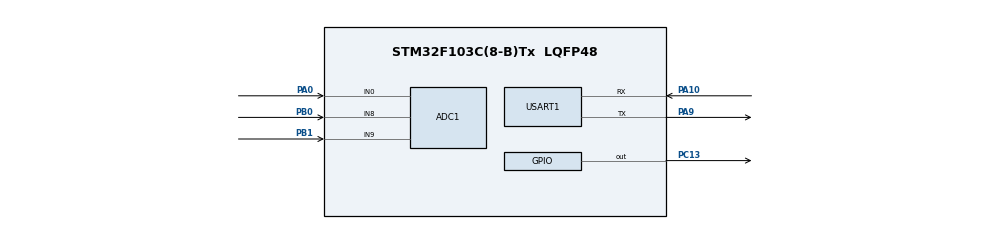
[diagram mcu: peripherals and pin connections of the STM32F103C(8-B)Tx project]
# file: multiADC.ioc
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ADC1.Channel-0\#ChannelRegularConversion=ADC_CHANNEL_0
ADC1.Channel-1\#ChannelRegularConversion=ADC_CHANNEL_0
ADC1.Channel-2\#ChannelRegularConversion=ADC_CHANNEL_0
ADC1.Channel-3\#ChannelRegularConversion=ADC_CHANNEL_0
ADC1.NbrOfConversion=4
ADC1.NbrOfConversionFlag=1
ADC1.Rank-0\#ChannelRegularConversion=1
ADC1.Rank-1\#ChannelRegularConversion=2
ADC1.Rank-2\#ChannelRegularConversion=3
ADC1.Rank-3\#ChannelRegularConversion=4
ADC1.SamplingTime-0\#ChannelRegularConversion=ADC_SAMPLETIME_1CYCLE_5
ADC1.SamplingTime-1\#ChannelRegularConversion=ADC_SAMPLETIME_1CYCLE_5
ADC1.SamplingTime-2\#ChannelRegularConversion=ADC_SAMPLETIME_1CYCLE_5
ADC1.SamplingTime-3\#ChannelRegularConversion=ADC_SAMPLETIME_1CYCLE_5
ADC1.master=1
Mcu.Family=STM32F1
Mcu.Name=STM32F103C(8-B)Tx
Mcu.Package=LQFP48
NVIC.ADC1_2_IRQn=true\:0\:0\:false\:false\:true\:true\:true
NVIC.PriorityGroup=NVIC_PRIORITYGROUP_4
PA0-WKUP.Signal=ADCx_IN0
PA10.Mode=Asynchronous
PA10.Signal=USART1_RX
PA9.Mode=Asynchronous
PA9.Signal=USART1_TX
PB0.Signal=ADCx_IN8
PB1.Signal=ADCx_IN9
PC13-TAMPER-RTC.Signal=GPIO_Output
ProjectManager.HeapSize=0x200
ProjectManager.StackSize=0x400
ProjectManager.TargetToolchain=Makefile
RCC.APB1Freq_Value=8000000
RCC.APB2Freq_Value=8000000
SH.ADCx_IN0.0=ADC1_IN0,IN0
SH.ADCx_IN8.0=ADC1_IN8,IN8
SH.ADCx_IN9.0=ADC1_IN9,IN9
USART1.VirtualMode=VM_ASYNC
VP_SYS_VS_ND.Mode=No_Debug
board=custom

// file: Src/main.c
/* USER CODE BEGIN Header */
/**
  ******************************************************************************
  * @file           : main.c
  * @brief          : Main program body
  ******************************************************************************
  ** This notice applies to any and all portions of this file
  * that are not between comment pairs USER CODE BEGIN and
  * USER CODE END. Other portions of this file, whether
  * inserted by the user or by software development tools
  * are owned by their respective copyright owners.
  *
  * COPYRIGHT(c) 2019 STMicroelectronics
  *
  * Redistribution and use in source and binary forms, with or without modification,
  * are permitted provided that the following conditions are met:
  *   1. Redistributions of source code must retain the above copyright notice,
  *      this list of conditions and the following disclaimer.
  *   2. Redistributions in binary form must reproduce the above copyright notice,
  *      this list of conditions and the following disclaimer in the documentation
  *      and/or other materials provided with the distribution.
  *   3. Neither the name of STMicroelectronics nor the names of its contributors
  *      may be used to endorse or promote products derived from this software
  *      without specific prior written permission.
  *
  * THIS SOFTWARE IS PROVIDED BY THE COPYRIGHT HOLDERS AND CONTRIBUTORS "AS IS"
  * AND ANY EXPRESS OR IMPLIED WARRANTIES, INCLUDING, BUT NOT LIMITED TO, THE
  * IMPLIED WARRANTIES OF MERCHANTABILITY AND FITNESS FOR A PARTICULAR PURPOSE ARE
  * DISCLAIMED. IN NO EVENT SHALL THE COPYRIGHT HOLDER OR CONTRIBUTORS BE LIABLE
  * FOR ANY DIRECT, INDIRECT, INCIDENTAL, SPECIAL, EXEMPLARY, OR CONSEQUENTIAL
  * DAMAGES (INCLUDING, BUT NOT LIMITED TO, PROCUREMENT OF SUBSTITUTE GOODS OR
  * SERVICES; LOSS OF USE, DATA, OR PROFITS; OR BUSINESS INTERRUPTION) HOWEVER
  * CAUSED AND ON ANY THEORY OF LIABILITY, WHETHER IN CONTRACT, STRICT LIABILITY,
  * OR TORT (INCLUDING NEGLIGENCE OR OTHERWISE) ARISING IN ANY WAY OUT OF THE USE
  * OF THIS SOFTWARE, EVEN IF ADVISED OF THE POSSIBILITY OF SUCH DAMAGE.
  *
  ******************************************************************************
  */
/* USER CODE END Header */

#include "main.h"

ADC_HandleTypeDef hadc1;

UART_HandleTypeDef huart1;

/* USER CODE BEGIN PV */
int count = 0;
uint16_t val[2];
uint8_t serial[4];
/* USER CODE END PV */

void SystemClock_Config(void);
static void MX_GPIO_Init(void);
static void MX_ADC1_Init(void);
static void MX_USART1_UART_Init(void);

int main(void)
{

  /* MCU Configuration--------------------------------------------------------*/

  /* Reset of all peripherals, Initializes the Flash interface and the Systick. */
  HAL_Init();

  /* Configure the system clock */
  SystemClock_Config();

  /* Initialize all configured peripherals */
  MX_GPIO_Init();
  MX_ADC1_Init();
  MX_USART1_UART_Init();

  /* Infinite loop */
  while (1)
  {
	HAL_ADC_Start(&hadc1);
	HAL_ADC_PollForConversion(&hadc1, 1000);
	val[0] = HAL_ADC_GetValue(&hadc1);

	HAL_ADC_PollForConversion(&hadc1, 1000);
	val[1] = HAL_ADC_GetValue(&hadc1);

	HAL_ADC_Stop(&hadc1);

	HAL_GPIO_TogglePin(GPIOC, GPIO_PIN_13);

	serial[0] = (uint8_t) ((val[0] >> 8) & 0xFF);
	serial[1] = (uint8_t) ((val[0] >> 0) & 0xFF);
	serial[2] = (uint8_t) ((val[1] >> 8) & 0xFF);
	serial[3] = (uint8_t) ((val[1] >> 0) & 0xFF);

	HAL_UART_Transmit(&huart1, serial, sizeof(serial), 1000);

	HAL_Delay(250);
  }
}

void HAL_ADC_ConvCpltCallback(ADC_HandleTypeDef* hadc) {

	/*if ((count % 2) == 0) {
		sConfig.Channel = ADC_CHANNEL_0;
		sConfig.Rank = ADC_REGULAR_RANK_1;
		sConfig.SamplingTime = ADC_SAMPLETIME_1CYCLE_5;
		HAL_ADC_ConfigChannel(&hadc1, &sConfig);
	}

	if (count % 2) {
		sConfig.Channel = ADC_CHANNEL_1;
		sConfig.Rank = ADC_REGULAR_RANK_1;
		sConfig.SamplingTime = ADC_SAMPLETIME_1CYCLE_5;
		HAL_ADC_ConfigChannel(&hadc1, &sConfig);
	}*/

	//count++;

	/*int val = HAL_ADC_GetValue(&hadc1);
	if (val > 2000) {
		HAL_GPIO_TogglePin(GPIOC, GPIO_PIN_13);
	}*/

}

void SystemClock_Config(void)
{
  RCC_OscInitTypeDef RCC_OscInitStruct = {0};
  RCC_ClkInitTypeDef RCC_ClkInitStruct = {0};
  RCC_PeriphCLKInitTypeDef PeriphClkInit = {0};

  /** Initializes the CPU, AHB and APB busses clocks
  */
  RCC_OscInitStruct.OscillatorType = RCC_OSCILLATORTYPE_HSI;
  RCC_OscInitStruct.HSIState = RCC_HSI_ON;
  RCC_OscInitStruct.HSICalibrationValue = RCC_HSICALIBRATION_DEFAULT;
  RCC_OscInitStruct.PLL.PLLState = RCC_PLL_NONE;
  if (HAL_RCC_OscConfig(&RCC_OscInitStruct) != HAL_OK)
  {
    Error_Handler();
  }
  /** Initializes the CPU, AHB and APB busses clocks
  */
  RCC_ClkInitStruct.ClockType = RCC_CLOCKTYPE_HCLK|RCC_CLOCKTYPE_SYSCLK
                              |RCC_CLOCKTYPE_PCLK1|RCC_CLOCKTYPE_PCLK2;
  RCC_ClkInitStruct.SYSCLKSource = RCC_SYSCLKSOURCE_HSI;
  RCC_ClkInitStruct.AHBCLKDivider = RCC_SYSCLK_DIV1;
  RCC_ClkInitStruct.APB1CLKDivider = RCC_HCLK_DIV1;
  RCC_ClkInitStruct.APB2CLKDivider = RCC_HCLK_DIV1;

  if (HAL_RCC_ClockConfig(&RCC_ClkInitStruct, FLASH_LATENCY_0) != HAL_OK)
  {
    Error_Handler();
  }
  PeriphClkInit.PeriphClockSelection = RCC_PERIPHCLK_ADC;
  PeriphClkInit.AdcClockSelection = RCC_ADCPCLK2_DIV2;
  if (HAL_RCCEx_PeriphCLKConfig(&PeriphClkInit) != HAL_OK)
  {
    Error_Handler();
  }
}

static void MX_ADC1_Init(void)
{

  ADC_ChannelConfTypeDef sConfig = {0};

  /** Common config
  */
  hadc1.Instance = ADC1;
  hadc1.Init.ScanConvMode = ENABLE; // enable to read from different ranks
  hadc1.Init.ContinuousConvMode = ENABLE;
  hadc1.Init.DiscontinuousConvMode = DISABLE;
  hadc1.Init.ExternalTrigConv = ADC_SOFTWARE_START;
  hadc1.Init.DataAlign = ADC_DATAALIGN_RIGHT;
  hadc1.Init.NbrOfConversion = 2;
  if (HAL_ADC_Init(&hadc1) != HAL_OK)
  {
    Error_Handler();
  }
  /** Configure Regular Channel
  */
  sConfig.Channel = ADC_CHANNEL_0;
  sConfig.Rank = ADC_REGULAR_RANK_1;
  sConfig.SamplingTime = ADC_SAMPLETIME_1CYCLE_5;
  if (HAL_ADC_ConfigChannel(&hadc1, &sConfig) != HAL_OK)
  {
    Error_Handler();
  }
  /** Configure Regular Channel
  */
  sConfig.Channel = ADC_CHANNEL_1;
  sConfig.Rank = ADC_REGULAR_RANK_2;
  if (HAL_ADC_ConfigChannel(&hadc1, &sConfig) != HAL_OK)
  {
    Error_Handler();
  }

}

static void MX_USART1_UART_Init(void)
{

  huart1.Instance = USART1;
  huart1.Init.BaudRate = 115200;
  huart1.Init.WordLength = UART_WORDLENGTH_8B;
  huart1.Init.StopBits = UART_STOPBITS_1;
  huart1.Init.Parity = UART_PARITY_NONE;
  huart1.Init.Mode = UART_MODE_TX_RX;
  huart1.Init.HwFlowCtl = UART_HWCONTROL_NONE;
  huart1.Init.OverSampling = UART_OVERSAMPLING_16;
  if (HAL_UART_Init(&huart1) != HAL_OK)
  {
    Error_Handler();
  }

}

static void MX_GPIO_Init(void)
{
  GPIO_InitTypeDef GPIO_InitStruct = {0};

  /* GPIO Ports Clock Enable */
  __HAL_RCC_GPIOC_CLK_ENABLE();
  __HAL_RCC_GPIOA_CLK_ENABLE();
  __HAL_RCC_GPIOB_CLK_ENABLE();

  /*Configure GPIO pin Output Level */
  HAL_GPIO_WritePin(GPIOC, GPIO_PIN_13, GPIO_PIN_RESET);

  /*Configure GPIO pin : PC13 */
  GPIO_InitStruct.Pin = GPIO_PIN_13;
  GPIO_InitStruct.Mode = GPIO_MODE_OUTPUT_PP;
  GPIO_InitStruct.Pull = GPIO_NOPULL;
  GPIO_InitStruct.Speed = GPIO_SPEED_FREQ_LOW;
  HAL_GPIO_Init(GPIOC, &GPIO_InitStruct);

}

void Error_Handler(void)
{
}

/************************ (C) COPYRIGHT STMicroelectronics *****END OF FILE****/
